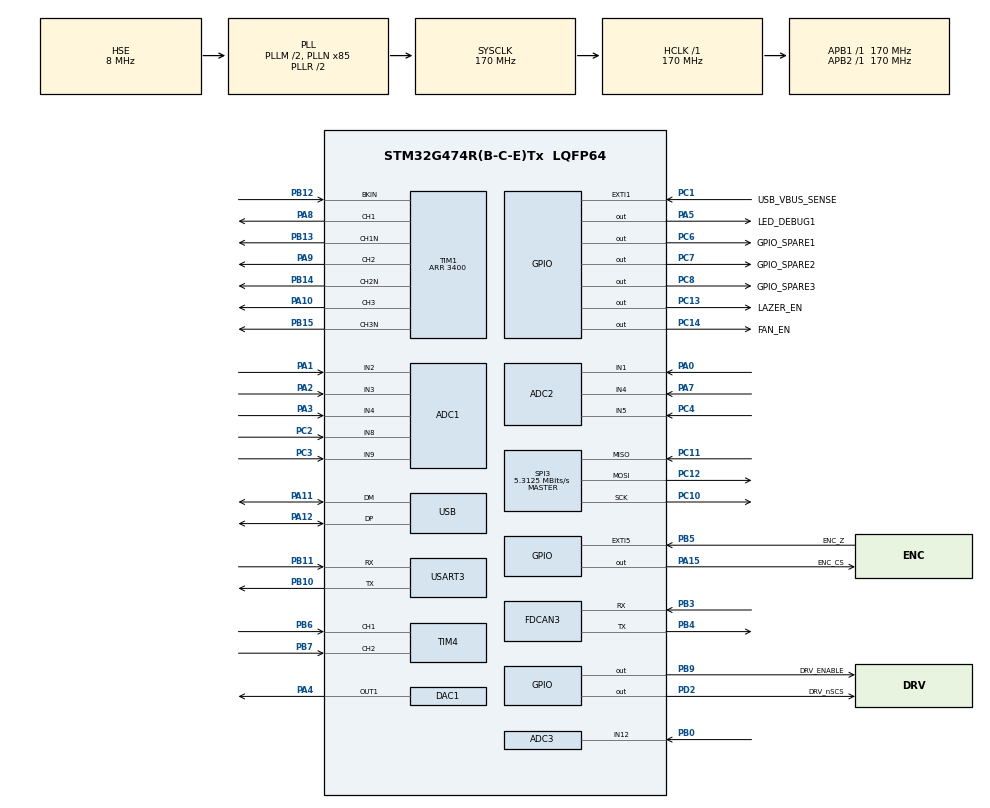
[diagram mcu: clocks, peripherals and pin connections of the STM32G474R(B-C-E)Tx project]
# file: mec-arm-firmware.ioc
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ADC1.ClockPrescaler=ADC_CLOCK_SYNC_PCLK_DIV4
ADC1.EnableInjectedConversion=ENABLE
ADC1.EnableRegularConversion=DISABLE
ADC1.ExternalTrigInjecConv=ADC_EXTERNALTRIGINJEC_T1_TRGO2
ADC1.InjNumberOfConversion=1
ADC1.InjectedChannel-1\#ChannelInjectedConversion=ADC_CHANNEL_2
ADC1.InjectedOffsetNumber-1\#ChannelInjectedConversion=ADC_OFFSET_NONE
ADC1.InjectedRank-1\#ChannelInjectedConversion=1
ADC1.InjectedSamplingTime-1\#ChannelInjectedConversion=ADC_SAMPLETIME_12CYCLES_5
ADC1.master=1
ADC2.Channel-0\#ChannelRegularConversion=ADC_CHANNEL_1
ADC2.Channel-3\#ChannelRegularConversion=ADC_CHANNEL_5
ADC2.ClockPrescaler=ADC_CLOCK_SYNC_PCLK_DIV4
ADC2.ContinuousConvMode=ENABLE
ADC2.DMAContinuousRequests=ENABLE
ADC2.EnableInjectedConversion=ENABLE
ADC2.ExternalTrigInjecConv=ADC_EXTERNALTRIGINJEC_T1_TRGO2
ADC2.InjNumberOfConversion=1
ADC2.InjectedChannel-5\#ChannelInjectedConversion=ADC_CHANNEL_4
ADC2.InjectedOffsetNumber-5\#ChannelInjectedConversion=ADC_OFFSET_NONE
ADC2.InjectedRank-5\#ChannelInjectedConversion=1
ADC2.InjectedSamplingTime-5\#ChannelInjectedConversion=ADC_SAMPLETIME_12CYCLES_5
ADC2.NbrOfConversion=2
ADC2.NbrOfConversionFlag=1
ADC2.OffsetNumber-0\#ChannelRegularConversion=ADC_OFFSET_NONE
ADC2.OffsetNumber-3\#ChannelRegularConversion=ADC_OFFSET_NONE
ADC2.Rank-0\#ChannelRegularConversion=1
ADC2.Rank-3\#ChannelRegularConversion=2
ADC2.SamplingTime-0\#ChannelRegularConversion=ADC_SAMPLETIME_47CYCLES_5
ADC2.SamplingTime-3\#ChannelRegularConversion=ADC_SAMPLETIME_247CYCLES_5
ADC3.ClockPrescaler=ADC_CLOCK_SYNC_PCLK_DIV4
ADC3.EnableAnalogWatchDog1=false
ADC3.EnableInjectedConversion=ENABLE
ADC3.EnableRegularConversion=DISABLE
ADC3.ExternalTrigInjecConv=ADC_EXTERNALTRIGINJEC_T1_TRGO2
ADC3.InjNumberOfConversion=1
ADC3.InjectedChannel-1\#ChannelInjectedConversion=ADC_CHANNEL_12
ADC3.InjectedOffsetNumber-1\#ChannelInjectedConversion=ADC_OFFSET_NONE
ADC3.InjectedRank-1\#ChannelInjectedConversion=1
ADC3.InjectedSamplingTime-1\#ChannelInjectedConversion=ADC_SAMPLETIME_12CYCLES_5
ADC3.Rank1_Channel=ADC_CHANNEL_12
ADC3.master=1
COMP1.Hysteresis=COMP_HYSTERESIS_MEDIUM
COMP2.Hysteresis=COMP_HYSTERESIS_MEDIUM
COMP4.Hysteresis=COMP_HYSTERESIS_MEDIUM
DAC3.DAC_Channel-DAC_OUT2_Int=DAC_CHANNEL_2
Dma.ADC2.0.Direction=DMA_PERIPH_TO_MEMORY
Dma.ADC2.0.EventEnable=DISABLE
Dma.ADC2.0.Instance=DMA1_Channel1
Dma.ADC2.0.MemDataAlignment=DMA_MDATAALIGN_HALFWORD
Dma.ADC2.0.MemInc=DMA_MINC_ENABLE
Dma.ADC2.0.Mode=DMA_CIRCULAR
Dma.ADC2.0.PeriphDataAlignment=DMA_PDATAALIGN_HALFWORD
Dma.ADC2.0.PeriphInc=DMA_PINC_DISABLE
Dma.ADC2.0.Polarity=HAL_DMAMUX_REQ_GEN_RISING
Dma.ADC2.0.Priority=DMA_PRIORITY_LOW
Dma.ADC2.0.RequestNumber=1
Dma.ADC2.0.SignalID=NONE
Dma.ADC2.0.SyncEnable=DISABLE
Dma.ADC2.0.SyncPolarity=HAL_DMAMUX_SYNC_NO_EVENT
Dma.ADC2.0.SyncRequestNumber=1
Dma.ADC2.0.SyncSignalID=NONE
Dma.Request0=ADC2
FDCAN3.CalculateBaudRateNominal=999999
FDCAN3.CalculateTimeBitNominal=1000
FDCAN3.CalculateTimeQuantumNominal=58.82352941176471
FDCAN3.DataPrescaler=10
FDCAN3.DataSyncJumpWidth=3
FDCAN3.DataTimeSeg1=13
FDCAN3.DataTimeSeg2=3
FDCAN3.NominalPrescaler=10
FDCAN3.NominalSyncJumpWidth=3
FDCAN3.NominalTimeSeg1=13
FDCAN3.NominalTimeSeg2=3
Mcu.Family=STM32G4
Mcu.Name=STM32G474R(B-C-E)Tx
Mcu.Package=LQFP64
NVIC.ADC1_2_IRQn=true\:1\:0\:true\:false\:true\:true\:true\:true
NVIC.EXTI1_IRQn=true\:7\:0\:true\:false\:true\:true\:true\:true
NVIC.EXTI9_5_IRQn=true\:2\:0\:true\:false\:true\:true\:true\:true
NVIC.FDCAN3_IT0_IRQn=true\:4\:0\:true\:false\:true\:true\:true\:true
NVIC.PriorityGroup=NVIC_PRIORITYGROUP_4
NVIC.SPI3_IRQn=true\:3\:0\:true\:false\:true\:true\:true\:true
NVIC.TIM1_BRK_TIM15_IRQn=true\:0\:0\:false\:false\:true\:true\:true\:true
NVIC.USART3_IRQn=true\:5\:0\:true\:false\:true\:true\:true\:true
NVIC.USB_LP_IRQn=true\:6\:0\:true\:false\:true\:false\:true\:true
PA0.Mode=IN1-Single-Ended
PA0.Signal=ADC2_IN1
PA1.Signal=SharedAnalog_PA1
PA10.Signal=S_TIM1_CH3
PA11.Mode=Device
PA11.Signal=USB_DM
PA12.Mode=Device
PA12.Signal=USB_DP
PA13.Mode=Serial_Wire
PA13.Signal=SYS_JTMS-SWDIO
PA14.Mode=Serial_Wire
PA14.Signal=SYS_JTCK-SWCLK
PA15.GPIO_Label=ENC_CS
PA15.GPIO_Speed=GPIO_SPEED_FREQ_HIGH
PA15.PinState=GPIO_PIN_SET
PA15.Signal=GPIO_Output
PA2.Mode=IN3-Single-Ended
PA2.Signal=ADC1_IN3
PA3.Mode=IN4-Single-Ended
PA3.Signal=ADC1_IN4
PA4.Signal=COMP_DAC11_group
PA5.GPIO_Label=LED_DEBUG1
PA5.Signal=GPIO_Output
PA7.Signal=SharedAnalog_PA7
PA8.Signal=S_TIM1_CH1
PA9.Signal=S_TIM1_CH2
PB0.Signal=SharedAnalog_PB0
PB10.Mode=Asynchronous
PB10.Signal=USART3_TX
PB11.Mode=Asynchronous
PB11.Signal=USART3_RX
PB12.Mode=Activate-Break-Input
PB12.Signal=TIM1_BKIN
PB13.Mode=PWM Generation1 CH1 CH1N
PB13.Signal=TIM1_CH1N
PB14.Mode=PWM Generation2 CH2 CH2N
PB14.Signal=TIM1_CH2N
PB15.Mode=PWM Generation3 CH3 CH3N
PB15.Signal=TIM1_CH3N
PB3.Mode=FDCAN_Activate
PB3.Signal=FDCAN3_RX
PB4.Mode=FDCAN_Activate
PB4.Signal=FDCAN3_TX
PB5.GPIO_Label=ENC_Z
PB5.Signal=GPXTI5
PB6.Signal=S_TIM4_CH1
PB7.Signal=S_TIM4_CH2
PB9.GPIO_Label=DRV_ENABLE
PB9.Signal=GPIO_Output
PC1.GPIO_Label=USB_VBUS_SENSE
PC1.Signal=GPXTI1
PC10.Mode=Full_Duplex_Master
PC10.Signal=SPI3_SCK
PC11.Mode=Full_Duplex_Master
PC11.Signal=SPI3_MISO
PC12.Mode=Full_Duplex_Master
PC12.Signal=SPI3_MOSI
PC13.GPIO_Label=LAZER_EN
PC13.Signal=GPIO_Output
PC14-OSC32_IN.GPIO_Label=FAN_EN
PC14-OSC32_IN.Signal=GPIO_Output
PC2.Mode=IN8-Single-Ended
PC2.Signal=ADC1_IN8
PC3.Mode=IN9-Single-Ended
PC3.Signal=ADC1_IN9
PC4.Mode=IN5-Single-Ended
PC4.Signal=ADC2_IN5
PC6.GPIO_Label=GPIO_SPARE1
PC6.Signal=GPIO_Output
PC7.GPIO_Label=GPIO_SPARE2
PC7.Signal=GPIO_Output
PC8.GPIO_Label=GPIO_SPARE3
PC8.Signal=GPIO_Output
PD2.GPIO_Label=DRV_nSCS
PD2.GPIO_Speed=GPIO_SPEED_FREQ_HIGH
PD2.PinState=GPIO_PIN_SET
PD2.Signal=GPIO_Output
PF0-OSC_IN.Mode=HSE-External-Oscillator
PF0-OSC_IN.Signal=RCC_OSC_IN
PF1-OSC_OUT.Mode=HSE-External-Oscillator
PF1-OSC_OUT.Signal=RCC_OSC_OUT
ProjectManager.HeapSize=0x400
ProjectManager.StackSize=0x1000
ProjectManager.TargetToolchain=CMake
RCC.ADC12Freq_Value=170000000
RCC.ADC345Freq_Value=170000000
RCC.AHBFreq_Value=170000000
RCC.APB1Freq_Value=170000000
RCC.APB1TimFreq_Value=170000000
RCC.APB2Freq_Value=170000000
RCC.APB2TimFreq_Value=170000000
RCC.CK48CLockSelection=RCC_USBCLKSOURCE_HSI48
RCC.CortexFreq_Value=170000000
RCC.EXTERNAL_CLOCK_VALUE=12288000
RCC.HCLKFreq_Value=170000000
RCC.HSE_VALUE=8000000
RCC.HSI48_VALUE=48000000
RCC.HSI_VALUE=16000000
RCC.LSE_VALUE=32768
RCC.PLLM=RCC_PLLM_DIV2
RCC.PLLN=85
RCC.PLLSourceVirtual=RCC_PLLSOURCE_HSE
RCC.SYSCLKFreq_VALUE=170000000
RCC.SYSCLKSource=RCC_SYSCLKSOURCE_PLLCLK
RCC.USBFreq_Value=48000000
RCC.VCOOutputFreq_Value=340000000
SH.COMP_DAC11_group.0=DAC1_OUT1,DAC_OUT1
SH.S_TIM1_CH1.0=TIM1_CH1,PWM Generation1 CH1 CH1N
SH.S_TIM1_CH2.0=TIM1_CH2,PWM Generation2 CH2 CH2N
SH.S_TIM1_CH3.0=TIM1_CH3,PWM Generation3 CH3 CH3N
SH.S_TIM4_CH1.0=TIM4_CH1,Encoder_Interface
SH.S_TIM4_CH2.0=TIM4_CH2,Encoder_Interface
SH.SharedAnalog_PA1.0=ADC1_IN2,IN2-Single-Ended
SH.SharedAnalog_PA1.1=COMP1_INP,INP
SH.SharedAnalog_PA7.0=ADC2_IN4,IN4-Single-Ended
SH.SharedAnalog_PA7.1=COMP2_INP,INP
SH.SharedAnalog_PB0.0=ADC3_IN12,IN12-Single-Ended
SH.SharedAnalog_PB0.1=COMP4_INP,INP
SPI3.BaudRatePrescaler=SPI_BAUDRATEPRESCALER_32
SPI3.CLKPhase=SPI_PHASE_2EDGE
SPI3.CalculateBaudRate=5.3125 MBits/s
SPI3.DataSize=SPI_DATASIZE_16BIT
SPI3.Direction=SPI_DIRECTION_2LINES
SPI3.Mode=SPI_MODE_MASTER
SPI3.VirtualType=VM_MASTER
TIM1.AutoReloadPreload=TIM_AUTORELOAD_PRELOAD_ENABLE
TIM1.Break2Filter=8
TIM1.Break2State=TIM_BREAK2_ENABLE
TIM1.BreakFilter=8
TIM1.BreakPolarity=TIM_BREAKPOLARITY_LOW
TIM1.Channel-PWM\ Generation1\ CH1\ CH1N=TIM_CHANNEL_1
TIM1.Channel-PWM\ Generation2\ CH2\ CH2N=TIM_CHANNEL_2
TIM1.Channel-PWM\ Generation3\ CH3\ CH3N=TIM_CHANNEL_3
TIM1.Channel-PWM\ Generation4\ No\ Output=TIM_CHANNEL_4
TIM1.CounterMode=TIM_COUNTERMODE_CENTERALIGNED1
TIM1.DeadTime=20
TIM1.OCMode_PWM-PWM\ Generation4\ No\ Output=TIM_OCMODE_PWM2
TIM1.OffStateIDLEMode=TIM_OSSI_ENABLE
TIM1.PeriodNoDither=3400
TIM1.PulseNoDither_4=3399
TIM1.RepetitionCounter=1
TIM1.SourceBRK2COMP1=TIM_BREAKINPUTSOURCE_ENABLE
TIM1.SourceBRK2COMP2=TIM_BREAKINPUTSOURCE_ENABLE
TIM1.SourceBRK2COMP4=TIM_BREAKINPUTSOURCE_ENABLE
TIM1.SourceBRKDigInputPolarity=TIM_BREAKINPUTSOURCE_POLARITY_HIGH
TIM1.TIM_MasterOutputTrigger2=TIM_TRGO2_OC4REF
TIM4.EncoderMode=TIM_ENCODERMODE_TI12
TIM4.IC1Filter=8
TIM4.IC2Filter=8
USART3.VirtualMode-Asynchronous=VM_ASYNC
USB_DEVICE.CLASS_NAME_FS=CDC
USB_DEVICE.VirtualMode=Cdc
USB_DEVICE.VirtualModeFS=Cdc_FS
VP_COMP1_VS_DAC3OUT1.Mode=INM_DAC3OUT1
VP_COMP2_VS_DAC3OUT2.Mode=INM_DAC3OUT2
VP_COMP4_VS_DAC3OUT2.Mode=INM_DAC3OUT2
VP_CORDIC_VS_CORDIC.Mode=CORDIC_Activate
VP_DAC3_VS_DACI1.Mode=DAC_OUT1_Int
VP_DAC3_VS_DACI2.Mode=DAC_OUT2_Int
VP_RCC_VS_USB.Mode=USB_FS
VP_SYS_VS_DBSignals.Mode=DisableDeadBatterySignals
VP_TIM1_VS_no_output4.Mode=PWM Generation4 No Output
VP_USB_DEVICE_VS_USB_DEVICE_CDC_FS.Mode=CDC_FS
board=custom

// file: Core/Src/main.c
/* USER CODE BEGIN Header */
/**
  ******************************************************************************
  * @file           : main.c
  * @brief          : Main program body
  ******************************************************************************
  * @attention
  *
  * Copyright (c) 2026 STMicroelectronics.
  * All rights reserved.
  *
  * This software is licensed under terms that can be found in the LICENSE file
  * in the root directory of this software component.
  * If no LICENSE file comes with this software, it is provided AS-IS.
  *
  ******************************************************************************
  */
/* USER CODE END Header */
#include "main.h"
#include "adc.h"
#include "comp.h"
#include "cordic.h"
#include "dac.h"
#include "dma.h"
#include "fdcan.h"
#include "spi.h"
#include "tim.h"
#include "usart.h"
#include "usb_device.h"
#include "gpio.h"

void SystemClock_Config(void);

int main(void)
{

  /* MCU Configuration--------------------------------------------------------*/

  /* Reset of all peripherals, Initializes the Flash interface and the Systick. */
  HAL_Init();

  /* Configure the system clock */
  SystemClock_Config();

  /* Initialize all configured peripherals */
  MX_GPIO_Init();
  MX_DMA_Init();
  MX_TIM1_Init();
  MX_ADC1_Init();
  MX_ADC2_Init();
  MX_ADC3_Init();
  MX_COMP1_Init();
  MX_COMP2_Init();
  MX_COMP4_Init();
  MX_DAC1_Init();
  MX_DAC3_Init();
  MX_FDCAN3_Init();
  MX_SPI3_Init();
  MX_TIM4_Init();
  MX_USART3_UART_Init();
  MX_USB_Device_Init();
  MX_CORDIC_Init();
  /* USER CODE BEGIN 2 */

  // Gate driver stays asleep
  HAL_GPIO_WritePin(DRV_ENABLE_GPIO_Port, DRV_ENABLE_Pin, GPIO_PIN_RESET);
  /* USER CODE END 2 */

  /* Infinite loop */
  /* USER CODE BEGIN WHILE */
  while (1)
  {

    HAL_GPIO_TogglePin(LED_DEBUG1_GPIO_Port, LED_DEBUG1_Pin);
    HAL_Delay(250);   // 2 Hz blink

    /* USER CODE END WHILE */

  }
}

void SystemClock_Config(void)
{
  RCC_OscInitTypeDef RCC_OscInitStruct = {0};
  RCC_ClkInitTypeDef RCC_ClkInitStruct = {0};
  RCC_CRSInitTypeDef pInit = {0};

  /** Configure the main internal regulator output voltage
  */
  HAL_PWREx_ControlVoltageScaling(PWR_REGULATOR_VOLTAGE_SCALE1_BOOST);

  /** Initializes the RCC Oscillators according to the specified parameters
  * in the RCC_OscInitTypeDef structure.
  */
  RCC_OscInitStruct.OscillatorType = RCC_OSCILLATORTYPE_HSI48|RCC_OSCILLATORTYPE_HSE;
  RCC_OscInitStruct.HSEState = RCC_HSE_ON;
  RCC_OscInitStruct.HSI48State = RCC_HSI48_ON;
  RCC_OscInitStruct.PLL.PLLState = RCC_PLL_ON;
  RCC_OscInitStruct.PLL.PLLSource = RCC_PLLSOURCE_HSE;
  RCC_OscInitStruct.PLL.PLLM = RCC_PLLM_DIV2;
  RCC_OscInitStruct.PLL.PLLN = 85;
  RCC_OscInitStruct.PLL.PLLP = RCC_PLLP_DIV2;
  RCC_OscInitStruct.PLL.PLLQ = RCC_PLLQ_DIV2;
  RCC_OscInitStruct.PLL.PLLR = RCC_PLLR_DIV2;
  if (HAL_RCC_OscConfig(&RCC_OscInitStruct) != HAL_OK)
  {
    Error_Handler();
  }

  /** Initializes the CPU, AHB and APB buses clocks
  */
  RCC_ClkInitStruct.ClockType = RCC_CLOCKTYPE_HCLK|RCC_CLOCKTYPE_SYSCLK
                              |RCC_CLOCKTYPE_PCLK1|RCC_CLOCKTYPE_PCLK2;
  RCC_ClkInitStruct.SYSCLKSource = RCC_SYSCLKSOURCE_PLLCLK;
  RCC_ClkInitStruct.AHBCLKDivider = RCC_SYSCLK_DIV1;
  RCC_ClkInitStruct.APB1CLKDivider = RCC_HCLK_DIV1;
  RCC_ClkInitStruct.APB2CLKDivider = RCC_HCLK_DIV1;

  if (HAL_RCC_ClockConfig(&RCC_ClkInitStruct, FLASH_LATENCY_4) != HAL_OK)
  {
    Error_Handler();
  }

  /** Enable the SYSCFG APB clock
  */
  __HAL_RCC_CRS_CLK_ENABLE();

  /** Configures CRS
  */
  pInit.Prescaler = RCC_CRS_SYNC_DIV1;
  pInit.Source = RCC_CRS_SYNC_SOURCE_USB;
  pInit.Polarity = RCC_CRS_SYNC_POLARITY_RISING;
  pInit.ReloadValue = __HAL_RCC_CRS_RELOADVALUE_CALCULATE(48000000,1000);
  pInit.ErrorLimitValue = 34;
  pInit.HSI48CalibrationValue = 32;

  HAL_RCCEx_CRSConfig(&pInit);
}

void Error_Handler(void)
{
  /* USER CODE BEGIN Error_Handler_Debug */

  // Disable the gate driver
    HAL_GPIO_WritePin(DRV_ENABLE_GPIO_Port, DRV_ENABLE_Pin, GPIO_PIN_RESET);

  // Solid LED for debug
  HAL_GPIO_WritePin(LED_DEBUG1_GPIO_Port, LED_DEBUG1_Pin, GPIO_PIN_SET);  // solid on = error

  /* User can add his own implementation to report the HAL error return state */
  __disable_irq();
  while (1)
  {
  }
  /* USER CODE END Error_Handler_Debug */
}
